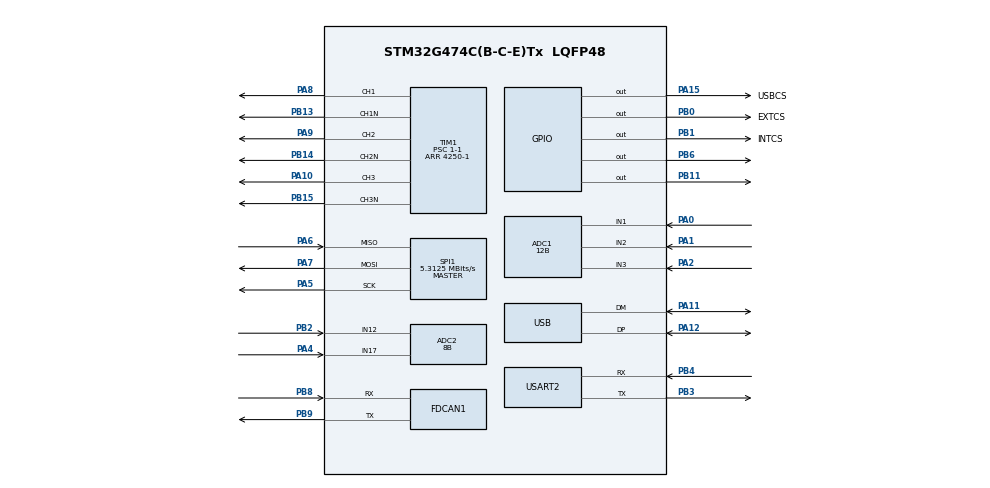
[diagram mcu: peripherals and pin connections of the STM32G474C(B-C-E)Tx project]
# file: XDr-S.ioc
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ADC1.Channel-0\#ChannelRegularConversion=ADC_CHANNEL_1
ADC1.Channel-1\#ChannelRegularConversion=ADC_CHANNEL_2
ADC1.Channel-2\#ChannelRegularConversion=ADC_CHANNEL_3
ADC1.DMAContinuousRequests=ENABLE
ADC1.ExternalTrigConv=ADC_EXTERNALTRIG_T1_TRGO
ADC1.ExternalTrigConvEdge=ADC_EXTERNALTRIGCONVEDGE_FALLING
ADC1.NbrOfConversion=3
ADC1.NbrOfConversionFlag=1
ADC1.OffsetNumber-0\#ChannelRegularConversion=ADC_OFFSET_NONE
ADC1.OffsetNumber-1\#ChannelRegularConversion=ADC_OFFSET_NONE
ADC1.OffsetNumber-2\#ChannelRegularConversion=ADC_OFFSET_NONE
ADC1.OversamplingMode=ENABLE
ADC1.Rank-0\#ChannelRegularConversion=1
ADC1.Rank-1\#ChannelRegularConversion=2
ADC1.Rank-2\#ChannelRegularConversion=3
ADC1.Ratio=ADC_OVERSAMPLING_RATIO_16
ADC1.Resolution=ADC_RESOLUTION_12B
ADC1.RightBitShift=ADC_RIGHTBITSHIFT_4
ADC1.SamplingTime-0\#ChannelRegularConversion=ADC_SAMPLETIME_2CYCLES_5
ADC1.SamplingTime-1\#ChannelRegularConversion=ADC_SAMPLETIME_2CYCLES_5
ADC1.SamplingTime-2\#ChannelRegularConversion=ADC_SAMPLETIME_2CYCLES_5
ADC1.master=1
ADC2.Channel-3\#ChannelRegularConversion=ADC_CHANNEL_12
ADC2.Channel-4\#ChannelRegularConversion=ADC_CHANNEL_17
ADC2.DMAContinuousRequests=ENABLE
ADC2.ExternalTrigConv=ADC_EXTERNALTRIG_T2_TRGO
ADC2.NbrOfConversion=2
ADC2.NbrOfConversionFlag=1
ADC2.OffsetNumber-3\#ChannelRegularConversion=ADC_OFFSET_NONE
ADC2.OffsetNumber-4\#ChannelRegularConversion=ADC_OFFSET_NONE
ADC2.Rank-3\#ChannelRegularConversion=1
ADC2.Rank-4\#ChannelRegularConversion=2
ADC2.Resolution=ADC_RESOLUTION_8B
ADC2.SamplingTime-3\#ChannelRegularConversion=ADC_SAMPLETIME_2CYCLES_5
ADC2.SamplingTime-4\#ChannelRegularConversion=ADC_SAMPLETIME_2CYCLES_5
Dma.ADC1.0.Direction=DMA_PERIPH_TO_MEMORY
Dma.ADC1.0.EventEnable=DISABLE
Dma.ADC1.0.Instance=DMA1_Channel1
Dma.ADC1.0.MemDataAlignment=DMA_MDATAALIGN_HALFWORD
Dma.ADC1.0.MemInc=DMA_MINC_ENABLE
Dma.ADC1.0.Mode=DMA_NORMAL
Dma.ADC1.0.PeriphDataAlignment=DMA_PDATAALIGN_HALFWORD
Dma.ADC1.0.PeriphInc=DMA_PINC_DISABLE
Dma.ADC1.0.Polarity=HAL_DMAMUX_REQ_GEN_RISING
Dma.ADC1.0.Priority=DMA_PRIORITY_HIGH
Dma.ADC1.0.RequestNumber=1
Dma.ADC1.0.SignalID=NONE
Dma.ADC1.0.SyncEnable=DISABLE
Dma.ADC1.0.SyncPolarity=HAL_DMAMUX_SYNC_NO_EVENT
Dma.ADC1.0.SyncRequestNumber=1
Dma.ADC1.0.SyncSignalID=NONE
Dma.ADC2.5.Direction=DMA_PERIPH_TO_MEMORY
Dma.ADC2.5.EventEnable=DISABLE
Dma.ADC2.5.Instance=DMA1_Channel4
Dma.ADC2.5.MemDataAlignment=DMA_MDATAALIGN_HALFWORD
Dma.ADC2.5.MemInc=DMA_MINC_ENABLE
Dma.ADC2.5.Mode=DMA_NORMAL
Dma.ADC2.5.PeriphDataAlignment=DMA_PDATAALIGN_HALFWORD
Dma.ADC2.5.PeriphInc=DMA_PINC_DISABLE
Dma.ADC2.5.Polarity=HAL_DMAMUX_REQ_GEN_RISING
Dma.ADC2.5.Priority=DMA_PRIORITY_LOW
Dma.ADC2.5.RequestNumber=1
Dma.ADC2.5.SignalID=NONE
Dma.ADC2.5.SyncEnable=DISABLE
Dma.ADC2.5.SyncPolarity=HAL_DMAMUX_SYNC_NO_EVENT
Dma.ADC2.5.SyncRequestNumber=1
Dma.ADC2.5.SyncSignalID=NONE
Dma.Request0=ADC1
Dma.Request1=USART2_RX
Dma.Request2=USART2_TX
Dma.Request3=SPI1_RX
Dma.Request4=SPI1_TX
Dma.Request5=ADC2
Dma.SPI1_RX.3.Direction=DMA_PERIPH_TO_MEMORY
Dma.SPI1_RX.3.EventEnable=DISABLE
Dma.SPI1_RX.3.Instance=DMA1_Channel5
Dma.SPI1_RX.3.MemDataAlignment=DMA_MDATAALIGN_HALFWORD
Dma.SPI1_RX.3.MemInc=DMA_MINC_ENABLE
Dma.SPI1_RX.3.Mode=DMA_NORMAL
Dma.SPI1_RX.3.PeriphDataAlignment=DMA_PDATAALIGN_HALFWORD
Dma.SPI1_RX.3.PeriphInc=DMA_PINC_DISABLE
Dma.SPI1_RX.3.Polarity=HAL_DMAMUX_REQ_GEN_RISING
Dma.SPI1_RX.3.Priority=DMA_PRIORITY_LOW
Dma.SPI1_RX.3.RequestNumber=1
Dma.SPI1_RX.3.SignalID=NONE
Dma.SPI1_RX.3.SyncEnable=DISABLE
Dma.SPI1_RX.3.SyncPolarity=HAL_DMAMUX_SYNC_NO_EVENT
Dma.SPI1_RX.3.SyncRequestNumber=1
Dma.SPI1_RX.3.SyncSignalID=NONE
Dma.SPI1_TX.4.Direction=DMA_MEMORY_TO_PERIPH
Dma.SPI1_TX.4.EventEnable=DISABLE
Dma.SPI1_TX.4.Instance=DMA1_Channel6
Dma.SPI1_TX.4.MemDataAlignment=DMA_MDATAALIGN_HALFWORD
Dma.SPI1_TX.4.MemInc=DMA_MINC_ENABLE
Dma.SPI1_TX.4.Mode=DMA_NORMAL
Dma.SPI1_TX.4.PeriphDataAlignment=DMA_PDATAALIGN_HALFWORD
Dma.SPI1_TX.4.PeriphInc=DMA_PINC_DISABLE
Dma.SPI1_TX.4.Polarity=HAL_DMAMUX_REQ_GEN_RISING
Dma.SPI1_TX.4.Priority=DMA_PRIORITY_LOW
Dma.SPI1_TX.4.RequestNumber=1
Dma.SPI1_TX.4.SignalID=NONE
Dma.SPI1_TX.4.SyncEnable=DISABLE
Dma.SPI1_TX.4.SyncPolarity=HAL_DMAMUX_SYNC_NO_EVENT
Dma.SPI1_TX.4.SyncRequestNumber=1
Dma.SPI1_TX.4.SyncSignalID=NONE
Dma.USART2_RX.1.Direction=DMA_PERIPH_TO_MEMORY
Dma.USART2_RX.1.EventEnable=DISABLE
Dma.USART2_RX.1.Instance=DMA1_Channel2
Dma.USART2_RX.1.MemDataAlignment=DMA_MDATAALIGN_BYTE
Dma.USART2_RX.1.MemInc=DMA_MINC_ENABLE
Dma.USART2_RX.1.Mode=DMA_CIRCULAR
Dma.USART2_RX.1.PeriphDataAlignment=DMA_PDATAALIGN_BYTE
Dma.USART2_RX.1.PeriphInc=DMA_PINC_DISABLE
Dma.USART2_RX.1.Polarity=HAL_DMAMUX_REQ_GEN_RISING
Dma.USART2_RX.1.Priority=DMA_PRIORITY_LOW
Dma.USART2_RX.1.RequestNumber=1
Dma.USART2_RX.1.SignalID=NONE
Dma.USART2_RX.1.SyncEnable=DISABLE
Dma.USART2_RX.1.SyncPolarity=HAL_DMAMUX_SYNC_NO_EVENT
Dma.USART2_RX.1.SyncRequestNumber=1
Dma.USART2_RX.1.SyncSignalID=NONE
Dma.USART2_TX.2.Direction=DMA_MEMORY_TO_PERIPH
Dma.USART2_TX.2.EventEnable=DISABLE
Dma.USART2_TX.2.Instance=DMA1_Channel3
Dma.USART2_TX.2.MemDataAlignment=DMA_MDATAALIGN_BYTE
Dma.USART2_TX.2.MemInc=DMA_MINC_ENABLE
Dma.USART2_TX.2.Mode=DMA_NORMAL
Dma.USART2_TX.2.PeriphDataAlignment=DMA_PDATAALIGN_BYTE
Dma.USART2_TX.2.PeriphInc=DMA_PINC_DISABLE
Dma.USART2_TX.2.Polarity=HAL_DMAMUX_REQ_GEN_RISING
Dma.USART2_TX.2.Priority=DMA_PRIORITY_LOW
Dma.USART2_TX.2.RequestNumber=1
Dma.USART2_TX.2.SignalID=NONE
Dma.USART2_TX.2.SyncEnable=DISABLE
Dma.USART2_TX.2.SyncPolarity=HAL_DMAMUX_SYNC_NO_EVENT
Dma.USART2_TX.2.SyncRequestNumber=1
Dma.USART2_TX.2.SyncSignalID=NONE
FDCAN1.AutoRetransmission=ENABLE
FDCAN1.CalculateBaudRateNominal=999999
FDCAN1.CalculateTimeBitNominal=1000
FDCAN1.CalculateTimeQuantumNominal=58.82352941176471
FDCAN1.ClockDivider=FDCAN_CLOCK_DIV1
FDCAN1.DataSyncJumpWidth=3
FDCAN1.NominalPrescaler=10
FDCAN1.NominalTimeSeg1=12
FDCAN1.NominalTimeSeg2=4
FDCAN1.StdFiltersNbr=1
Mcu.Family=STM32G4
Mcu.Name=STM32G474C(B-C-E)Tx
Mcu.Package=LQFP48
NVIC.DMA1_Channel1_IRQn=true\:0\:1\:true\:false\:true\:false\:true\:true
NVIC.DMA1_Channel2_IRQn=true\:2\:1\:true\:false\:true\:false\:true\:true
NVIC.DMA1_Channel3_IRQn=true\:2\:1\:true\:false\:true\:false\:true\:true
NVIC.DMA1_Channel4_IRQn=true\:0\:0\:false\:false\:true\:false\:true\:true
NVIC.DMA1_Channel5_IRQn=true\:1\:0\:true\:false\:true\:false\:true\:true
NVIC.DMA1_Channel6_IRQn=true\:1\:0\:true\:false\:true\:false\:true\:true
NVIC.FDCAN1_IT0_IRQn=true\:0\:2\:false\:false\:true\:true\:true\:true
NVIC.PriorityGroup=NVIC_PRIORITYGROUP_2
NVIC.SPI1_IRQn=true\:1\:1\:true\:false\:true\:true\:true\:true
NVIC.TIM1_UP_TIM16_IRQn=true\:0\:0\:false\:false\:true\:true\:true\:true
NVIC.USART2_IRQn=true\:2\:2\:true\:false\:true\:true\:true\:true
NVIC.USB_LP_IRQn=true\:0\:0\:false\:false\:true\:false\:true\:true
PA0.Mode=IN1-Single-Ended
PA0.Signal=ADC1_IN1
PA1.Mode=IN2-Single-Ended
PA1.Signal=ADC1_IN2
PA10.Signal=S_TIM1_CH3
PA11.Mode=Device
PA11.Signal=USB_DM
PA12.Mode=Device
PA12.Signal=USB_DP
PA13.Mode=Serial_Wire
PA13.Signal=SYS_JTMS-SWDIO
PA14.Mode=Serial_Wire
PA14.Signal=SYS_JTCK-SWCLK
PA15.GPIO_Label=USBCS
PA15.GPIO_Speed=GPIO_SPEED_FREQ_HIGH
PA15.Signal=GPIO_Output
PA2.Mode=IN3-Single-Ended
PA2.Signal=ADC1_IN3
PA4.Mode=IN17-Single-Ended
PA4.Signal=ADC2_IN17
PA5.Mode=Full_Duplex_Master
PA5.Signal=SPI1_SCK
PA6.Mode=Full_Duplex_Master
PA6.Signal=SPI1_MISO
PA7.Mode=Full_Duplex_Master
PA7.Signal=SPI1_MOSI
PA8.Signal=S_TIM1_CH1
PA9.Signal=S_TIM1_CH2
PB0.GPIO_Label=EXTCS
PB0.Signal=GPIO_Output
PB1.GPIO_Label=INTCS
PB1.Signal=GPIO_Output
PB11.Signal=GPIO_Output
PB13.Mode=PWM Generation1 CH1 CH1N
PB13.Signal=TIM1_CH1N
PB14.Mode=PWM Generation2 CH2 CH2N
PB14.Signal=TIM1_CH2N
PB15.Mode=PWM Generation3 CH3 CH3N
PB15.Signal=TIM1_CH3N
PB2.Mode=IN12-Single-Ended
PB2.Signal=ADC2_IN12
PB3.Mode=Asynchronous
PB3.Signal=USART2_TX
PB4.Mode=Asynchronous
PB4.Signal=USART2_RX
PB6.Signal=GPIO_Output
PB8-BOOT0.Mode=FDCAN_Activate
PB8-BOOT0.Signal=FDCAN1_RX
PB9.Mode=FDCAN_Activate
PB9.Signal=FDCAN1_TX
PF0-OSC_IN.Mode=HSE-External-Oscillator
PF0-OSC_IN.Signal=RCC_OSC_IN
PF1-OSC_OUT.Mode=HSE-External-Oscillator
PF1-OSC_OUT.Signal=RCC_OSC_OUT
ProjectManager.HeapSize=0x800
ProjectManager.StackSize=0x1200
ProjectManager.TargetToolchain=CMake
RCC.ADC12Freq_Value=170000000
RCC.ADC345Freq_Value=170000000
RCC.AHBFreq_Value=170000000
RCC.APB1Freq_Value=170000000
RCC.APB1TimFreq_Value=170000000
RCC.APB2Freq_Value=170000000
RCC.APB2TimFreq_Value=170000000
RCC.CK48CLockSelection=RCC_USBCLKSOURCE_HSI48
RCC.CortexFreq_Value=170000000
RCC.EXTERNAL_CLOCK_VALUE=12288000
RCC.HCLKFreq_Value=170000000
RCC.HSE_VALUE=25000000
RCC.HSI48_VALUE=48000000
RCC.HSI_VALUE=16000000
RCC.LSE_VALUE=32768
RCC.PLLM=RCC_PLLM_DIV5
RCC.PLLN=68
RCC.PLLSourceVirtual=RCC_PLLSOURCE_HSE
RCC.SYSCLKFreq_VALUE=170000000
RCC.SYSCLKSource=RCC_SYSCLKSOURCE_PLLCLK
RCC.USBFreq_Value=48000000
RCC.VCOOutputFreq_Value=340000000
SH.S_TIM1_CH1.0=TIM1_CH1,PWM Generation1 CH1 CH1N
SH.S_TIM1_CH2.0=TIM1_CH2,PWM Generation2 CH2 CH2N
SH.S_TIM1_CH3.0=TIM1_CH3,PWM Generation3 CH3 CH3N
SPI1.BaudRatePrescaler=SPI_BAUDRATEPRESCALER_32
SPI1.CLKPhase=SPI_PHASE_2EDGE
SPI1.CLKPolarity=SPI_POLARITY_HIGH
SPI1.CalculateBaudRate=5.3125 MBits/s
SPI1.DataSize=SPI_DATASIZE_16BIT
SPI1.Direction=SPI_DIRECTION_2LINES
SPI1.Mode=SPI_MODE_MASTER
SPI1.VirtualType=VM_MASTER
STMicroelectronics.X-CUBE-ALGOBUILD.1.5.0.LibraryCcDSPOoLibraryJjDSPOoLibrary=true
TIM1.AutoReloadPreload=TIM_AUTORELOAD_PRELOAD_ENABLE
TIM1.AutomaticOutput=TIM_AUTOMATICOUTPUT_ENABLE
TIM1.Channel-PWM\ Generation1\ CH1\ CH1N=TIM_CHANNEL_1
TIM1.Channel-PWM\ Generation2\ CH2\ CH2N=TIM_CHANNEL_2
TIM1.Channel-PWM\ Generation3\ CH3\ CH3N=TIM_CHANNEL_3
TIM1.Channel-PWM\ Generation4\ No\ Output=TIM_CHANNEL_4
TIM1.CounterMode=TIM_COUNTERMODE_CENTERALIGNED1
TIM1.DeadTime=17
TIM1.DeadTimePreload=ENABLE
TIM1.OffStateRunMode=TIM_OSSR_ENABLE
TIM1.PeriodNoDither=4250-1
TIM1.Prescaler=1-1
TIM1.PulseNoDither_4=4248
TIM1.TIM_MasterOutputTrigger=TIM_TRGO_OC4REF
TIM2.PeriodNoDither=5000-1
TIM2.Prescaler=170-1
TIM2.TIM_MasterOutputTrigger=TIM_TRGO_UPDATE
USART2.FIFOMode=FIFOMODE_ENABLE
USART2.RXFIFOThreshold=RXFIFO_THRESHOLD_1EIGHTHFULL
USART2.TXFIFOThreshold=TXFIFO_THRESHOLD_1EIGHTHFULL
USART2.VirtualMode-Asynchronous=VM_ASYNC
USB_DEVICE.CLASS_NAME_FS=CUSTOM_HID
USB_DEVICE.VirtualMode=CustomHid
USB_DEVICE.VirtualModeFS=Custom_Hid_FS
VP_STMicroelectronics.X-CUBE-ALGOBUILD_VS_DSPOoLibraryJjLibrary_1.5.0_1.5.0.Mode=DSPOoLibraryJjLibrary
VP_SYS_VS_DBSignals.Mode=DisableDeadBatterySignals
VP_TIM1_VS_ClockSourceINT.Mode=Internal
VP_TIM1_VS_no_output4.Mode=PWM Generation4 No Output
VP_TIM2_VS_ClockSourceINT.Mode=Internal
VP_USB_DEVICE_VS_USB_DEVICE_CUSTOM_HID_FS.Mode=CUSTOM_HID_FS
board=custom

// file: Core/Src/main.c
/* USER CODE BEGIN Header */
/**
 ******************************************************************************
 * @file           : main.c
 * @brief          : Main program body
 ******************************************************************************
 * @attention
 *
 * Copyright (c) 2026 STMicroelectronics.
 * All rights reserved.
 *
 * This software is licensed under terms that can be found in the LICENSE file
 * in the root directory of this software component.
 * If no LICENSE file comes with this software, it is provided AS-IS.
 *
 ******************************************************************************
 */
/* USER CODE END Header */
#include "main.h"
#include "adc.h"
#include "dma.h"
#include "fdcan.h"
#include "spi.h"
#include "tim.h"
#include "usart.h"
#include "usb_device.h"
#include "gpio.h"

/* USER CODE BEGIN Includes */
#include "bsp_cfg.h"
// #include "bsp_flash.h"
#include "xfoc_main.h"
/* USER CODE END Includes */

void SystemClock_Config(void);

int main(void)
{

  /* USER CODE BEGIN 1 */
    // mcu_iap_app_init();
  /* USER CODE END 1 */

  /* MCU Configuration--------------------------------------------------------*/

  /* Reset of all peripherals, Initializes the Flash interface and the Systick. */
  HAL_Init();

  /* Configure the system clock */
  SystemClock_Config();

  /* Initialize all configured peripherals */
  MX_GPIO_Init();
  MX_DMA_Init();
  MX_SPI1_Init();
  MX_ADC2_Init();
  MX_TIM1_Init();
  MX_USART2_UART_Init();
  MX_FDCAN1_Init();
  MX_ADC1_Init();
  MX_TIM2_Init();
  MX_USB_Device_Init();
  /* USER CODE BEGIN 2 */
    // 1、初始化驱动层 （存储-iap-状态-传感-gate-通讯）
    if (!bsp_base_init())
        Error_Handler();

    // 2、启动xdr foc驱动
    if (!xfoc_start())
        Error_Handler();
  /* USER CODE END 2 */

  /* Infinite loop */
    while (1) {

    }
}

void SystemClock_Config(void)
{
  LL_FLASH_SetLatency(LL_FLASH_LATENCY_4);
  while(LL_FLASH_GetLatency() != LL_FLASH_LATENCY_4)
  {
  }
  LL_PWR_EnableRange1BoostMode();
  LL_RCC_HSE_Enable();
   /* Wait till HSE is ready */
  while(LL_RCC_HSE_IsReady() != 1)
  {
  }

  LL_RCC_HSI48_Enable();
   /* Wait till HSI48 is ready */
  while(LL_RCC_HSI48_IsReady() != 1)
  {
  }

  LL_RCC_PLL_ConfigDomain_SYS(LL_RCC_PLLSOURCE_HSE, LL_RCC_PLLM_DIV_5, 68, LL_RCC_PLLR_DIV_2);
  LL_RCC_PLL_EnableDomain_SYS();
  LL_RCC_PLL_Enable();
   /* Wait till PLL is ready */
  while(LL_RCC_PLL_IsReady() != 1)
  {
  }

  LL_RCC_SetSysClkSource(LL_RCC_SYS_CLKSOURCE_PLL);
  LL_RCC_SetAHBPrescaler(LL_RCC_SYSCLK_DIV_2);
   /* Wait till System clock is ready */
  while(LL_RCC_GetSysClkSource() != LL_RCC_SYS_CLKSOURCE_STATUS_PLL)
  {
  }

  /* Insure 1us transition state at intermediate medium speed clock*/
  for (__IO uint32_t i = (170 >> 1); i !=0; i--);

  /* Set AHB prescaler*/
  LL_RCC_SetAHBPrescaler(LL_RCC_SYSCLK_DIV_1);
  LL_RCC_SetAPB1Prescaler(LL_RCC_APB1_DIV_1);
  LL_RCC_SetAPB2Prescaler(LL_RCC_APB2_DIV_1);
  LL_SetSystemCoreClock(170000000);

   /* Update the time base */
  if (HAL_InitTick (TICK_INT_PRIORITY) != HAL_OK)
  {
    Error_Handler();
  }
}

void Error_Handler(void)
{
  /* USER CODE BEGIN Error_Handler_Debug */
    /* User can add his own implementation to report the HAL error return state
     */
    __disable_irq();
    while (1) {
    }
  /* USER CODE END Error_Handler_Debug */
}
#ifdef USE_FULL_ASSERT
/**
  * @brief  Reports the name of the source file and the source line number
  *         where the assert_param error has occurred.
  * @param  file: pointer to the source file name
  * @param  line: assert_param error line source number
  * @retval None
  */
void assert_failed(uint8_t *file, uint32_t line)
{
  /* USER CODE BEGIN 6 */
    /* User can add his own implementation to report the file name and line
       number, ex: printf("Wrong parameters value: file %s on line %d\r\n",
       file, line) */
  /* USER CODE END 6 */
}
#endif /* USE_FULL_ASSERT */
